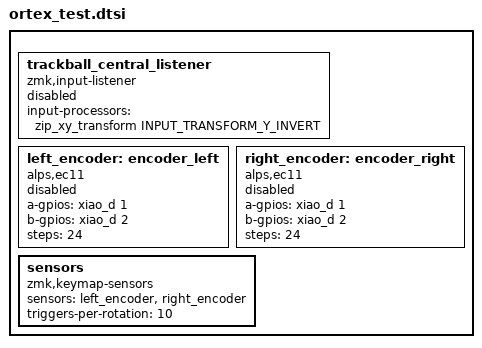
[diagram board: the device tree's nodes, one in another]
#include <input/processors.dtsi>
#include <dt-bindings/zmk/input_transform.h>

{

    //right hand trackball
    trackball_central_listener: trackball_central_listener {
        compatible = "zmk,input-listener";
        status = "disabled";
        input-processors = 
            <&zip_xy_transform INPUT_TRANSFORM_Y_INVERT>;         //Y軸反転
            //<&zip_xy_transform INPUT_TRANSFORM_XY_SWAP>,        //X軸とY軸の入れ替え
            //<&zip_xy_transform INPUT_TRANSFORM_X_INVERT>,       //X軸反転
            //<&zip_temp_layer 5 500>;                              //オートマウスレイヤーの選択
    };

    left_encoder: encoder_left {
        compatible = "alps,ec11";
        a-gpios = <&xiao_d 1 (GPIO_ACTIVE_HIGH | GPIO_PULL_UP)>;
        b-gpios = <&xiao_d 2 (GPIO_ACTIVE_HIGH | GPIO_PULL_UP)>;
        steps = <24>;
        status = "disabled";
    };

    right_encoder: encoder_right {
         compatible = "alps,ec11";
        a-gpios = <&xiao_d 1 (GPIO_ACTIVE_HIGH | GPIO_PULL_UP)>;
        b-gpios = <&xiao_d 2 (GPIO_ACTIVE_HIGH | GPIO_PULL_UP)>;
        steps = <24>;
        status = "disabled";
    };

    sensors: sensors {
        compatible = "zmk,keymap-sensors";
        sensors = <&left_encoder &right_encoder>;
        triggers-per-rotation = <10>;
    };

};
